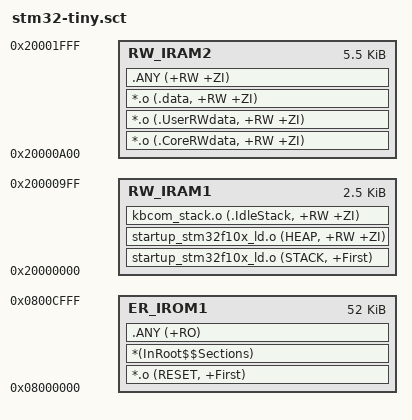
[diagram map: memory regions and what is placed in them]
; *************************************************************
; *** Scatter-Loading Description File generated by uVision ***
; *************************************************************

LR_IROM1 0x08000000 0x0000D000  {    ; load region size_region
  ER_IROM1 0x08000000 0x0000D000  {  ; load address = execution address
   *.o (RESET, +First)
   *(InRoot$$Sections)
   .ANY (+RO)
  }
  RW_IRAM1 0x20000000 0x00000A00  {  ; RW data
   startup_stm32f10x_ld.o (STACK, +First)
   startup_stm32f10x_ld.o (HEAP, +RW +ZI)
   kbcom_stack.o (.IdleStack, +RW +ZI)
;   kbstm32_stack.o (.BootStack, +RW +ZI)
  }
  RW_IRAM2 0x20000A00 0x00001600  {  ; RW data
   *.o (.CoreRWdata, +RW +ZI)
   *.o (.UserRWdata, +RW +ZI)
   *.o (.data, +RW +ZI)
   .ANY (+RW +ZI)
  }
}

